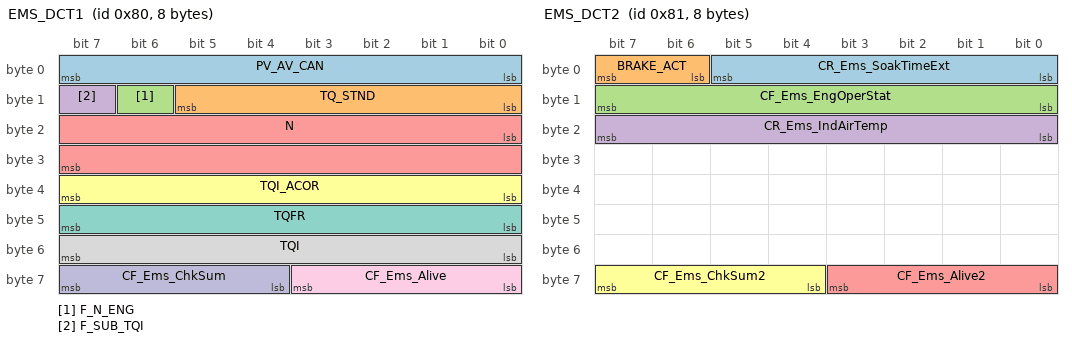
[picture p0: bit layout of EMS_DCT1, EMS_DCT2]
BO_ 128 EMS_DCT1: 8 XXX
    SG_ PV_AV_CAN : 0|8@1+ (0.3906,0) [0|99.603] "%" XXX
    SG_ TQ_STND : 8|6@1+ (10,0) [0|630] "Nm" XXX
    SG_ F_N_ENG : 14|1@1+ (1,0) [0|1] "" XXX
    SG_ F_SUB_TQI : 15|1@1+ (1,0) [0|1] "" XXX
    SG_ N : 16|16@1+ (0.25,0) [0|16383.8] "rpm" XXX
    SG_ TQI_ACOR : 32|8@1+ (0.390625,0) [0|99.6094] "%" XXX
    SG_ TQFR : 40|8@1+ (0.390625,0) [0|99.6094] "%" XXX
    SG_ TQI : 48|8@1+ (0.390625,0) [0|99.6094] "%" XXX
    SG_ CF_Ems_Alive : 56|4@1+ (1,0) [0|15] "" XXX
    SG_ CF_Ems_ChkSum : 60|4@1+ (1,0) [0|15] "" XXX

BO_ 129 EMS_DCT2: 8 XXX
    SG_ CR_Ems_SoakTimeExt : 0|6@1+ (5,0) [0|315] "Min" XXX
    SG_ BRAKE_ACT : 6|2@1+ (1,0) [0|3] "" XXX
    SG_ CF_Ems_EngOperStat : 8|8@1+ (1,0) [0|255] "" XXX
    SG_ CR_Ems_IndAirTemp : 16|8@1+ (0.75,-48) [-48|143.25] "" XXX
    SG_ CF_Ems_Alive2 : 56|4@1+ (1,0) [0|15] "" XXX
    SG_ CF_Ems_ChkSum2 : 60|4@1+ (1,0) [0|15] "" XXX

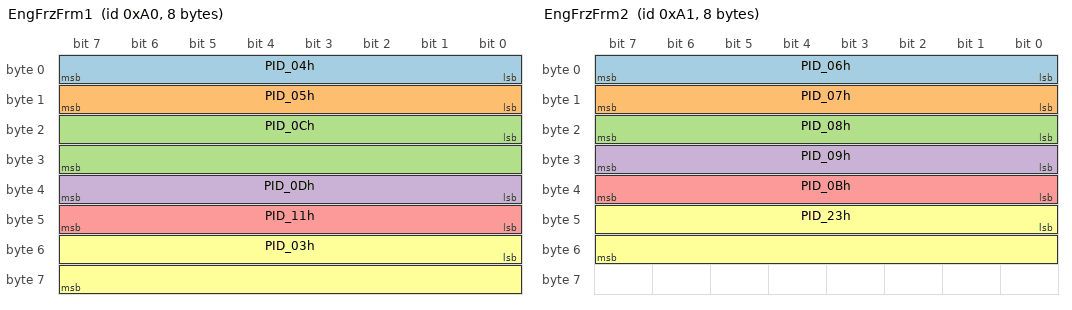
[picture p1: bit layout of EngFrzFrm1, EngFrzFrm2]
BO_ 160 EngFrzFrm1: 8 XXX
    SG_ PID_04h : 0|8@1+ (0.392157,0) [0|100] "%" XXX
    SG_ PID_05h : 8|8@1+ (1,-40) [-40|215] "" XXX
    SG_ PID_0Ch : 16|16@1+ (0.25,0) [0|16383.8] "rpm" XXX
    SG_ PID_0Dh : 32|8@1+ (1,0) [0|255] "km/h" XXX
    SG_ PID_11h : 40|8@1+ (0.392157,0) [0|100] "%" XXX
    SG_ PID_03h : 48|16@1+ (1,0) [0|65535] "" XXX

BO_ 161 EngFrzFrm2: 8 XXX
    SG_ PID_06h : 0|8@1+ (0.78125,-100) [-100|99.22] "%" XXX
    SG_ PID_07h : 8|8@1+ (0.78125,-100) [-100|99.22] "%" XXX
    SG_ PID_08h : 16|8@1+ (0.78125,-100) [-100|99.22] "%" XXX
    SG_ PID_09h : 24|8@1+ (0.78125,-100) [-100|99.22] "%" XXX
    SG_ PID_0Bh : 32|8@1+ (1,0) [0|255] "kPa" XXX
    SG_ PID_23h : 40|16@1+ (10,0) [0|655350] "kPa" XXX

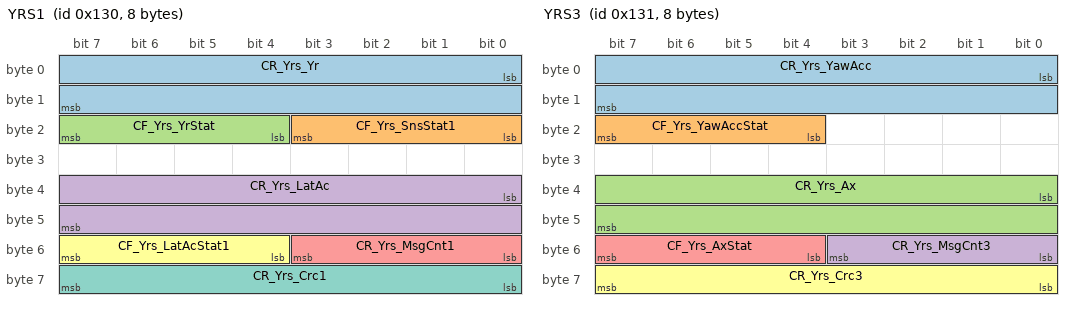
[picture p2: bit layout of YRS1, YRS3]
BO_ 304 YRS1: 8 XXX
    SG_ CR_Yrs_Yr : 0|16@1+ (0.005,-163.84) [-163.84|163.83] "" XXX
    SG_ CF_Yrs_SnsStat1 : 16|4@1+ (1,0) [0|15] "" XXX
    SG_ CF_Yrs_YrStat : 20|4@1+ (1,0) [0|15] "" XXX
    SG_ CR_Yrs_LatAc : 32|16@1+ (0.000127465,-4.17677) [-4.17677|4.17652] "g" XXX
    SG_ CR_Yrs_MsgCnt1 : 48|4@1+ (1,0) [0|15] "" XXX
    SG_ CF_Yrs_LatAcStat1 : 52|4@1+ (1,0) [0|15] "" XXX
    SG_ CR_Yrs_Crc1 : 56|8@1+ (1,0) [0|255] "" XXX

BO_ 305 YRS3: 8 XXX
    SG_ CR_Yrs_YawAcc : 0|16@1+ (0.125,-4096) [-4096|4095.75] "" XXX
    SG_ CF_Yrs_YawAccStat : 20|4@1+ (1,0) [0|15] "" XXX
    SG_ CR_Yrs_Ax : 32|16@1+ (0.000127465,-4.17677) [-4.17677|4.17652] "g" XXX
    SG_ CR_Yrs_MsgCnt3 : 48|4@1+ (1,0) [0|15] "" XXX
    SG_ CF_Yrs_AxStat : 52|4@1+ (1,0) [0|15] "" XXX
    SG_ CR_Yrs_Crc3 : 56|8@1+ (1,0) [0|255] "" XXX

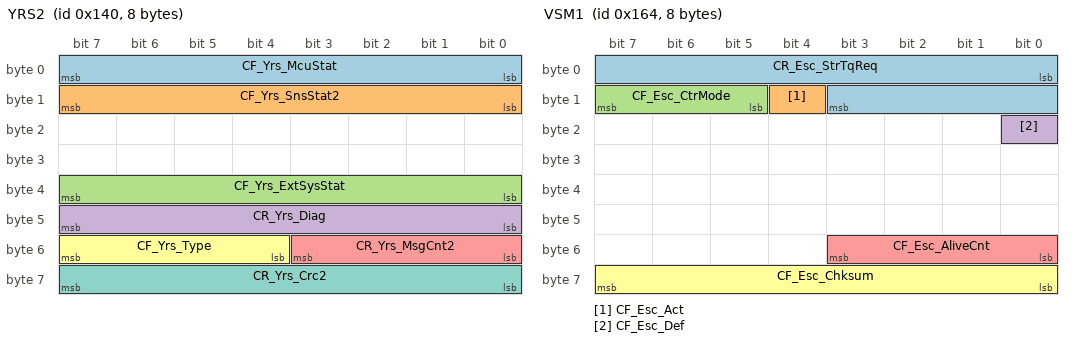
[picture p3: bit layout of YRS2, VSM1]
BO_ 320 YRS2: 8 XXX
    SG_ CF_Yrs_McuStat : 0|8@1+ (1,0) [0|255] "" XXX
    SG_ CF_Yrs_SnsStat2 : 8|8@1+ (1,0) [0|255] "" XXX
    SG_ CF_Yrs_ExtSysStat : 32|8@1+ (1,0) [0|255] "" XXX
    SG_ CR_Yrs_Diag : 40|8@1+ (1,0) [0|255] "" XXX
    SG_ CR_Yrs_MsgCnt2 : 48|4@1+ (1,0) [0|15] "" XXX
    SG_ CF_Yrs_Type : 52|4@1+ (1,0) [0|15] "" XXX
    SG_ CR_Yrs_Crc2 : 56|8@1+ (1,0) [0|255] "" XXX

BO_ 339 TCS1: 8 XXX
    SG_ TCS_REQ : 0|1@1+ (1,0) [0|1] "" XXX
    SG_ MSR_C_REQ : 1|1@1+ (1,0) [0|1] "" XXX
    SG_ TCS_PAS : 2|1@1+ (1,0) [0|1] "" XXX
    SG_ TCS_GSC : 3|1@1+ (1,0) [0|1] "" XXX
    SG_ CF_Esc_LimoInfo : 4|2@1+ (1,0) [0|3] "" XXX
    SG_ ABS_DIAG : 6|1@1+ (1,0) [0|1] "" XXX
    SG_ ABS_DEF : 7|1@1+ (1,0) [0|1] "" XXX
    SG_ TCS_DEF : 8|1@1+ (1,0) [0|1] "" XXX
    SG_ TCS_CTL : 9|1@1+ (1,0) [0|1] "" XXX
    SG_ ABS_ACT : 10|1@1+ (1,0) [0|1] "" XXX
    SG_ EBD_DEF : 11|1@1+ (1,0) [0|1] "" XXX
    SG_ ESP_PAS : 12|1@1+ (1,0) [0|1] "" XXX
    SG_ ESP_DEF : 13|1@1+ (1,0) [0|1] "" XXX
    SG_ ESP_CTL : 14|1@1+ (1,0) [0|1] "" XXX
    SG_ TCS_MFRN : 15|1@1+ (1,0) [0|1] "" XXX
    SG_ DBC_CTL : 16|1@1+ (1,0) [0|1] "" XXX
    SG_ DBC_PAS : 17|1@1+ (1,0) [0|1] "" XXX
    SG_ DBC_DEF : 18|1@1+ (1,0) [0|1] "" XXX
    SG_ HAC_CTL : 19|1@1+ (1,0) [0|1] "" XXX
    SG_ HAC_PAS : 20|1@1+ (1,0) [0|1] "" XXX
    SG_ HAC_DEF : 21|1@1+ (1,0) [0|1] "" XXX
    SG_ ESS_STAT : 22|2@1+ (1,0) [0|3] "" XXX
    SG_ TQI_TCS : 24|8@1+ (0.390625,0) [0|99.6094] "%" XXX
    SG_ TQI_MSR : 32|8@1+ (0.390625,0) [0|99.6094] "%" XXX
    SG_ TQI_SLW_TCS : 40|8@1+ (0.390625,0) [0|99.6094] "%" XXX
    SG_ CF_Esc_BrkCtl : 48|1@1+ (1,0) [0|1] "" XXX
    SG_ ESC_OFF_STEP : 49|2@1+ (1,0) [0|3] "" XXX
    SG_ _4WD_Status : 51|1@1+ (1,0) [0|1] "" XXX
    SG_ AliveCounter_TCS1 : 52|4@1+ (1,0) [0|1] "" XXX
    SG_ CheckSum_TCS1 : 56|8@1+ (1,0) [0|1] "" XXX

BO_ 356 VSM1: 8 XXX
    SG_ CR_Esc_StrTqReq : 0|12@1+ (0.01,-20.48) [-20.48|20.47] "Nm" XXX
    SG_ CF_Esc_Act : 12|1@1+ (1,0) [0|1] "" XXX
    SG_ CF_Esc_CtrMode : 13|3@1+ (1,0) [0|7] "" XXX
    SG_ CF_Esc_Def : 16|1@1+ (1,0) [0|1] "" XXX
    SG_ CF_Esc_AliveCnt : 48|4@1+ (1,0) [0|15] "" XXX
    SG_ CF_Esc_Chksum : 56|8@1+ (1,0) [0|255] "" XXX

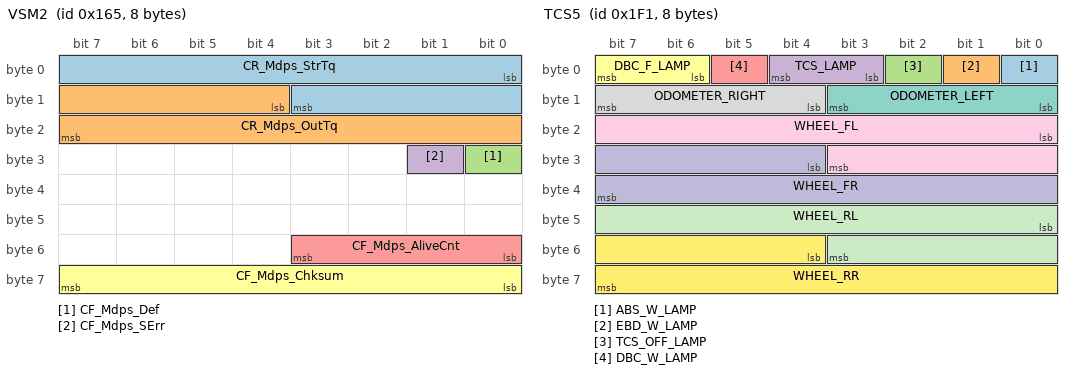
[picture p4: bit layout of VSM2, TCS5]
BO_ 357 VSM2: 8 XXX
    SG_ CR_Mdps_StrTq : 0|12@1+ (0.01,-20.48) [-20.48|20.47] "Nm" XXX
    SG_ CR_Mdps_OutTq : 12|12@1+ (0.1,-204.8) [-204.8|204.7] "" XXX
    SG_ CF_Mdps_Def : 24|1@1+ (1,0) [0|1] "" XXX
    SG_ CF_Mdps_SErr : 25|1@1+ (1,0) [0|1] "" XXX
    SG_ CF_Mdps_AliveCnt : 48|4@1+ (1,0) [0|15] "" XXX
    SG_ CF_Mdps_Chksum : 56|8@1+ (1,0) [0|255] "" XXX

BO_ 399 EMS_H2: 8 XXX
    SG_ R_TqAcnApvC : 0|8@1+ (0.2,0) [0|51] "Nm" XXX
    SG_ R_PAcnC : 8|8@1+ (125,0) [0|31875] "hPa" XXX
    SG_ TQI_B : 16|8@1+ (0.390625,0) [0|99.6094] "%" XXX
    SG_ SLD_VS : 24|8@1+ (1,0) [0|255] "km/h" XXX
    SG_ CF_CdaStat : 32|3@1+ (1,0) [0|7] "" XXX
    SG_ CF_Ems_IsgStat : 35|3@1+ (1,0) [0|7] "" XXX
    SG_ CF_Ems_OilChg : 38|1@1+ (1,0) [0|1] "" XXX
    SG_ CF_Ems_EtcLimpMod : 39|1@1+ (1,0) [0|1] "" XXX
    SG_ R_NEngIdlTgC : 40|8@1+ (10,0) [0|2550] "rpm" XXX
    SG_ CF_Ems_UpTarGr : 48|1@1+ (1,0) [0|1] "" XXX
    SG_ CF_Ems_DownTarGr : 49|1@1+ (1,0) [0|1] "" XXX
    SG_ CF_Ems_DesCurGr : 50|4@1+ (1,0) [0|15] "" XXX
    SG_ CF_Ems_SldAct : 54|1@1+ (1,0) [0|1] "" XXX
    SG_ CF_Ems_SldPosAct : 55|1@1+ (1,0) [0|1] "" XXX
    SG_ CF_Ems_HPresStat : 56|1@1+ (1,0) [0|1] "" XXX
    SG_ CF_Ems_IsgBuz : 57|1@1+ (1,0) [0|1] "" XXX
    SG_ CF_Ems_IdlStpFCO : 58|1@1+ (1,0) [0|1] "" XXX
    SG_ CF_Ems_FCopen : 59|1@1+ (1,0) [0|1] "" XXX
    SG_ CF_Ems_ActEcoAct : 60|1@1+ (1,0) [0|1] "" XXX
    SG_ CF_Ems_EngRunNorm : 61|1@1+ (1,0) [0|1] "" XXX
    SG_ CF_Ems_IsgStat2 : 62|2@1+ (2,0) [0|3] "" XXX

BO_ 497 TCS5: 8 XXX
    SG_ ABS_W_LAMP : 0|1@1+ (1,0) [0|1] "" XXX
    SG_ EBD_W_LAMP : 1|1@1+ (1,0) [0|1] "" XXX
    SG_ TCS_OFF_LAMP : 2|1@1+ (1,0) [0|1] "" XXX
    SG_ TCS_LAMP : 3|2@1+ (1,0) [0|3] "" XXX
    SG_ DBC_W_LAMP : 5|1@1+ (1,0) [0|1] "" XXX
    SG_ DBC_F_LAMP : 6|2@1+ (1,0) [0|3] "" XXX
    SG_ ODOMETER_LEFT : 8|4@1+ (1,0) [0|15] "m" XXX
    SG_ ODOMETER_RIGHT : 12|4@1+ (1,0) [0|15] "m" XXX
    SG_ WHEEL_FL : 16|12@1+ (0.125,0) [0|511.875] "km/h" XXX
    SG_ WHEEL_FR : 28|12@1+ (0.125,0) [0|511.875] "km/h" XXX
    SG_ WHEEL_RL : 40|12@1+ (0.125,0) [0|511.875] "km/h" XXX
    SG_ WHEEL_RR : 52|12@1+ (0.125,0) [0|511.875] "km/h" XXX

BO_ 544 ESP2: 8 XXX
    SG_ LAT_ACCEL : 0|11@1+ (0.01,-10.23) [-10.23|10.24] "m/s^2" XXX
    SG_ ESP2_AliveCounter_LSB : 11|3@1+ (1,0) [0|7] "" XXX
    SG_ LAT_ACCEL_STAT : 14|1@1+ (1,0) [0|1] "" XXX
    SG_ LAT_ACCEL_DIAG : 15|1@1+ (1,0) [0|1] "" XXX
    SG_ LONG_ACCEL : 16|11@1+ (0.01,-10.23) [-10.23|10.24] "m/s^2" XXX
    SG_ ESP2_AliveCounter_MSB : 27|1@1+ (1,0) [0|1] "" XXX
    SG_ ESP2_Checksum_LSB : 28|2@1+ (1,0) [0|3] "" XXX
    SG_ LONG_ACCEL_STAT : 30|1@1+ (1,0) [0|1] "" XXX
    SG_ LONG_ACCEL_DIAG : 31|1@1+ (1,0) [0|1] "" XXX
    SG_ CYL_PRES : 32|12@1+ (0.1,0) [0|409.5] "Bar" XXX
    SG_ ESP12_Checksum_MSB : 44|2@1+ (1,0) [0|3] "" XXX
    SG_ CYL_PRES_STAT : 46|1@1+ (1,0) [0|1] "" XXX
    SG_ CYL_PRESS_DIAG : 47|1@1+ (1,0) [0|1] "" XXX
    SG_ YAW_RATE : 48|13@1+ (0.01,-40.95) [-40.95|40.96] "" XXX
    SG_ CYL_PRES_FLAG : 61|1@1+ (1,0) [0|1] "" XXX
    SG_ YAW_RATE_STAT : 62|1@1+ (1,0) [0|1] "" XXX
    SG_ YAW_RATE_DIAG : 63|1@1+ (1,0) [0|1] "" XXX

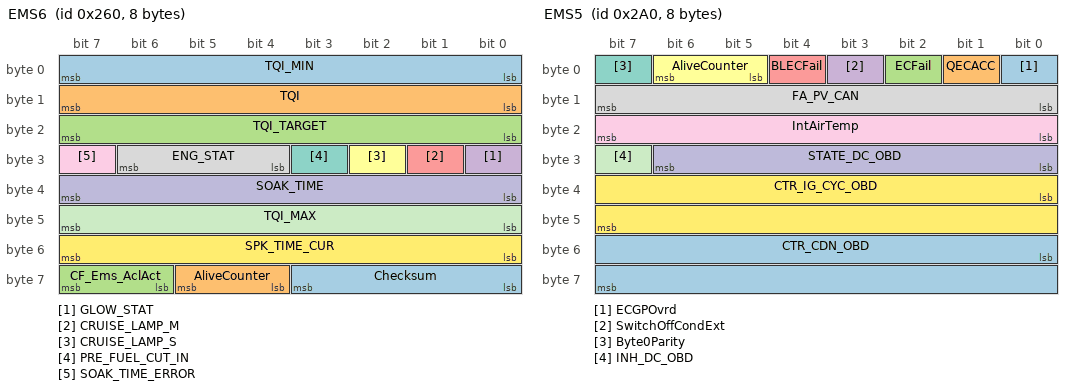
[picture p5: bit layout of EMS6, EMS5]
BO_ 608 EMS6: 8 XXX
    SG_ TQI_MIN : 0|8@1+ (0.390625,0) [0|99.6094] "%" XXX
    SG_ TQI : 8|8@1+ (0.390625,0) [0|99.6094] "%" XXX
    SG_ TQI_TARGET : 16|8@1+ (0.390625,0) [0|99.6094] "%" XXX
    SG_ GLOW_STAT : 24|1@1+ (1,0) [0|1] "" XXX
    SG_ CRUISE_LAMP_M : 25|1@1+ (1,0) [0|1] "" XXX
    SG_ CRUISE_LAMP_S : 26|1@1+ (1,0) [0|1] "" XXX
    SG_ PRE_FUEL_CUT_IN : 27|1@1+ (1,0) [0|1] "" XXX
    SG_ ENG_STAT : 28|3@1+ (1,0) [0|7] "" XXX
    SG_ SOAK_TIME_ERROR : 31|1@1+ (1,0) [0|1] "" XXX
    SG_ SOAK_TIME : 32|8@1+ (1,0) [0|255] "Min" XXX
    SG_ TQI_MAX : 40|8@1+ (0.390625,0) [0|99.6094] "%" XXX
    SG_ SPK_TIME_CUR : 48|8@1+ (0.375,-35.625) [-35.625|60] "" XXX
    SG_ Checksum : 56|4@1+ (1,0) [0|15] "" XXX
    SG_ AliveCounter : 60|2@1+ (1,0) [0|3] "" XXX
    SG_ CF_Ems_AclAct : 62|2@1+ (1,0) [0|3] "" XXX

BO_ 672 EMS5: 8 XXX
    SG_ ECGPOvrd : 0|1@1+ (1,0) [0|1] "" XXX
    SG_ QECACC : 1|1@1+ (1,0) [0|1] "" XXX
    SG_ ECFail : 2|1@1+ (1,0) [0|1] "" XXX
    SG_ SwitchOffCondExt : 3|1@1+ (1,0) [0|1] "" XXX
    SG_ BLECFail : 4|1@1+ (1,0) [0|1] "" XXX
    SG_ AliveCounter : 5|2@1+ (1,0) [0|3] "" XXX
    SG_ Byte0Parity : 7|1@1+ (1,0) [0|1] "" XXX
    SG_ FA_PV_CAN : 8|8@1+ (0.3906,0) [0|99.2] "%" XXX
    SG_ IntAirTemp : 16|8@1+ (0.75,-48) [-48|143.25] "" XXX
    SG_ STATE_DC_OBD : 24|7@1+ (1,0) [0|127] "" XXX
    SG_ INH_DC_OBD : 31|1@1+ (1,0) [0|1] "" XXX
    SG_ CTR_IG_CYC_OBD : 32|16@1+ (1,0) [0|65535] "" XXX
    SG_ CTR_CDN_OBD : 48|16@1+ (1,0) [0|65535] "" XXX

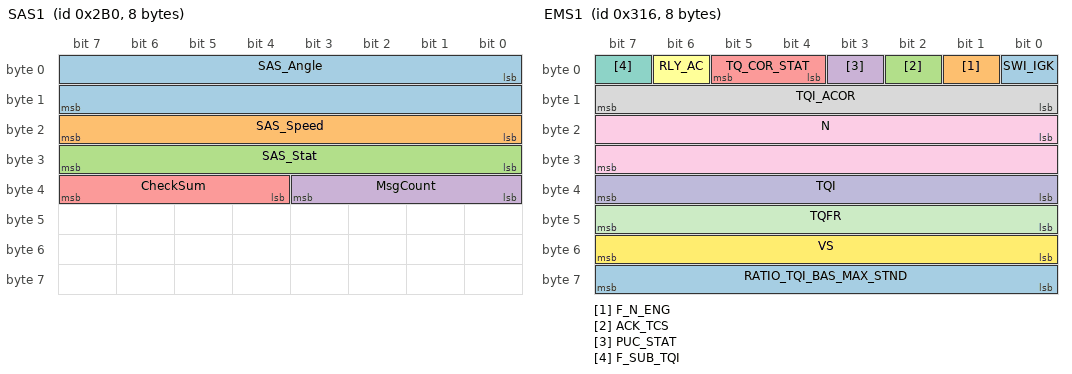
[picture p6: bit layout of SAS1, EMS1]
BO_ 688 SAS1: 8 XXX
    SG_ SAS_Angle : 0|16@1+ (0.1,0) [-3276.8|3276.7] "Deg" XXX
    SG_ SAS_Speed : 16|8@1+ (4,0) [0|1016] "" XXX
    SG_ SAS_Stat : 24|8@1+ (1,0) [0|255] "" XXX
    SG_ MsgCount : 32|4@1+ (1,0) [0|15] "" XXX
    SG_ CheckSum : 36|4@1+ (1,0) [0|15] "" XXX

BO_ 790 EMS1: 8 XXX
    SG_ SWI_IGK : 0|1@1+ (1,0) [0|1] "" XXX
    SG_ F_N_ENG : 1|1@1+ (1,0) [0|1] "" XXX
    SG_ ACK_TCS : 2|1@1+ (1,0) [0|1] "" XXX
    SG_ PUC_STAT : 3|1@1+ (1,0) [0|1] "" XXX
    SG_ TQ_COR_STAT : 4|2@1+ (1,0) [0|3] "" XXX
    SG_ RLY_AC : 6|1@1+ (1,0) [0|1] "" XXX
    SG_ F_SUB_TQI : 7|1@1+ (1,0) [0|1] "" XXX
    SG_ TQI_ACOR : 8|8@1+ (0.390625,0) [0|99.6094] "%" XXX
    SG_ N : 16|16@1+ (0.25,0) [0|16383.8] "rpm" XXX
    SG_ TQI : 32|8@1+ (0.390625,0) [0|99.6094] "%" XXX
    SG_ TQFR : 40|8@1+ (0.390625,0) [0|99.6094] "%" XXX
    SG_ VS : 48|8@1+ (1,0) [0|254] "km/h" XXX
    SG_ RATIO_TQI_BAS_MAX_STND : 56|8@1+ (0.0078,0) [0|2] "" XXX

BO_ 809 EMS2: 8 XXX
    SG_ TQ_STND : 0|6@1+ (10,0) [0|630] "Nm" XXX
    SG_ CAN_VERS : 0|6@1+ (1,0) [0|7.7] "" XXX
    SG_ CONF_TCU : 0|6@1+ (1,0) [0|63] "" XXX
    SG_ OBD_FRF_ACK : 0|6@1+ (1,0) [0|63] "" XXX
    SG_ MUL_CODE : 6|2@1+ (1,0) [0|3] "" XXX
    SG_ TEMP_ENG : 8|8@1+ (0.75,-48) [-48|143.25] "" XXX
    SG_ MAF_FAC_ALTI_MMV : 16|8@1+ (0.00781,0) [0|1.99155] "" XXX
    SG_ VB_OFF_ACT : 24|1@1+ (1,0) [0|1] "" XXX
    SG_ ACK_ES : 25|1@1+ (1,0) [0|1] "" XXX
    SG_ CONF_MIL_FMY : 26|3@1+ (1,0) [0|7] "" XXX
    SG_ OD_OFF_REQ : 29|1@1+ (1,0) [0|1] "" XXX
    SG_ ACC_ACT : 30|1@1+ (1,0) [0|1] "" XXX
    SG_ CLU_ACK : 31|1@1+ (1,0) [0|1] "" XXX
    SG_ BRAKE_ACT : 32|2@1+ (1,0) [0|3] "" XXX
    SG_ ENG_CHR : 34|4@1+ (1,0) [0|15] "" XXX
    SG_ GP_CTL : 38|2@1+ (1,0) [0|3] "" XXX
    SG_ TPS : 40|8@1+ (0.469484,-15.0235) [-15.0235|104.695] "%" XXX
    SG_ PV_AV_CAN : 48|8@1+ (0.3906,0) [0|99.603] "%" XXX
    SG_ ENG_VOL : 56|8@1+ (0.1,0) [0|25.5] "liter" XXX

BO_ 848 FATC: 8 XXX
    SG_ CR_Fatc_TqAcnOut : 0|8@1+ (0.2,0) [0|50.8] "Nm" XXX
    SG_ CF_Fatc_AcnRqSwi : 8|1@1+ (1,0) [0|1] "" XXX
    SG_ CF_Fatc_AcnCltEnRq : 9|1@1+ (1,0) [0|1] "" XXX
    SG_ CF_Fatc_EcvFlt : 10|1@1+ (1,0) [0|1] "" XXX
    SG_ CF_Fatc_BlwrOn : 11|1@1+ (1,0) [0|1] "" XXX
    SG_ CF_FATC_Iden : 12|2@1+ (1,0) [0|3] "" XXX
    SG_ CF_Fatc_BlwrMax : 14|1@1+ (1,0) [0|1] "" XXX
    SG_ CF_Fatc_EngStartReq : 15|1@1+ (1,0) [0|1] "" XXX
    SG_ CF_Fatc_IsgStopReq : 16|1@1+ (1,0) [0|1] "" XXX
    SG_ CF_Fatc_CtrInf : 17|3@1+ (1,0) [0|7] "" XXX
    SG_ CF_Fatc_MsgCnt : 20|4@1+ (1,0) [0|15] "" XXX
    SG_ CR_Fatc_OutTemp : 24|8@1+ (0.5,-40) [-40|60] "" XXX
    SG_ CR_Fatc_OutTempSns : 32|8@1+ (0.5,-40) [-40|60] "" XXX
    SG_ CF_Fatc_Compload : 40|3@1+ (1,0) [0|7] "" XXX
    SG_ CF_Fatc_ActiveEco : 43|1@1+ (1,0) [0|1] "" XXX
    SG_ CF_Fatc_AutoActivation : 44|1@1+ (1,0) [0|1] "" XXX
    SG_ CF_Fatc_DefSw : 45|1@1+ (1,0) [0|1] "" XXX
    SG_ CF_Fatc_PtcRlyStat : 46|1@1+ (1,0) [0|1] "" XXX
    SG_ CF_Fatc_ChkSum : 56|8@1+ (1,0) [0|255] "" XXX

BO_ 880 TCU3: 8 XXX
    SG_ N_TGT_LUP : 0|8@1+ (10,500) [500|3040] "rpm" XXX
    SG_ SLOPE_TCU : 8|6@1+ (0.5,-16) [-16|15.5] "%" XXX
    SG_ CF_Tcu_InhCda : 14|1@1+ (1,0) [0|1] "" XXX
    SG_ CF_Tcu_IsgInhib : 15|1@1+ (1,0) [0|1] "" XXX
    SG_ CF_Tcu_BkeOnReq : 16|2@1+ (1,0) [0|3] "" XXX
    SG_ CF_Tcu_NCStat : 18|2@1+ (1,0) [0|3] "" XXX
    SG_ CF_Tcu_TarGr : 20|4@1+ (1,0) [0|15] "" XXX
    SG_ CF_Tcu_ShfPatt : 24|4@1+ (1,0) [0|15] "" XXX
    SG_ CF_Tcu_InhVis : 28|1@1+ (1,0) [0|1] "" XXX
    SG_ CF_Tcu_PRelReq : 29|1@1+ (1,0) [0|1] "" XXX
    SG_ CF_Tcu_ITPhase : 30|1@1+ (1,0) [0|1] "" XXX
    SG_ CF_Tcu_ActEcoRdy : 31|1@1+ (1,0) [0|1] "" XXX
    SG_ CF_Tcu_TqGrdLim : 32|8@1+ (10,0) [0|2540] "Nm/s" XXX
    SG_ CR_Tcu_IsgTgtRPM : 40|8@1+ (20,0) [0|3500] "rpm" XXX
    SG_ TQI_TCU_INC : 48|8@1+ (0.390625,0) [0|99.6094] "%" XXX
    SG_ CF_Tcu_SbwPInfo : 56|1@1+ (1,0) [0|1] "" XXX
    SG_ CF_Tcu_SptRdy : 57|1@1+ (1,0) [0|1] "" XXX
    SG_ CF_Tcu_Alive3 : 58|2@1+ (1,0) [0|3] "" XXX
    SG_ CF_Tcu_ChkSum3 : 60|4@1+ (1,0) [0|15] "" XXX

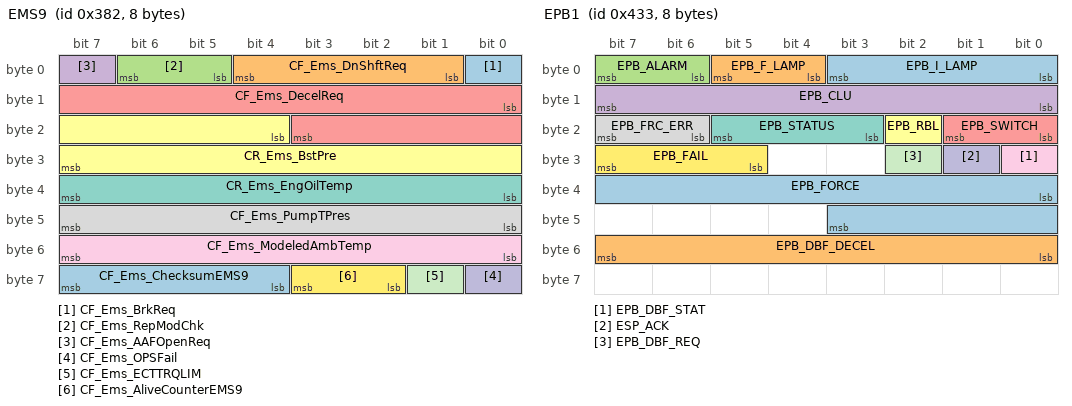
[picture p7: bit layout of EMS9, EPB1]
BO_ 898 EMS9: 8 XXX
    SG_ CF_Ems_BrkReq : 0|1@1+ (1,0) [0|1] "" XXX
    SG_ CF_Ems_DnShftReq : 1|4@1+ (1,0) [0|14] "" XXX
    SG_ CF_Ems_RepModChk : 5|2@1+ (1,0) [0|3] "" XXX
    SG_ CF_Ems_AAFOpenReq : 7|1@1+ (1,0) [0|1] "" XXX
    SG_ CF_Ems_DecelReq : 8|12@1+ (0.001,-4.094) [-4.094|0] "m/s^2" XXX
    SG_ CR_Ems_BstPre : 20|12@1+ (1.322,0) [0|4094] "hPa" XXX
    SG_ CR_Ems_EngOilTemp : 32|8@1+ (0.75,-40) [0|254] "" XXX
    SG_ CF_Ems_PumpTPres : 40|8@1+ (3.13725,0) [0|800] "kPa" XXX
    SG_ CF_Ems_ModeledAmbTemp : 48|8@1+ (0.5,-41) [-40|60] "" XXX
    SG_ CF_Ems_OPSFail : 56|1@1+ (1,0) [0|1] "" XXX
    SG_ CF_Ems_ECTTRQLIM : 57|1@1+ (1,0) [0|1] "" XXX
    SG_ CF_Ems_AliveCounterEMS9 : 58|2@1+ (1,0) [0|3] "" XXX
    SG_ CF_Ems_ChecksumEMS9 : 60|4@1+ (1,0) [0|15] "" XXX

BO_ 1075 EPB1: 8 XXX
    SG_ EPB_I_LAMP : 0|4@1+ (1,0) [0|15] "" XXX
    SG_ EPB_F_LAMP : 4|2@1+ (1,0) [0|3] "" XXX
    SG_ EPB_ALARM : 6|2@1+ (1,0) [0|3] "" XXX
    SG_ EPB_CLU : 8|8@1+ (1,0) [0|255] "" XXX
    SG_ EPB_SWITCH : 16|2@1+ (1,0) [0|3] "" XXX
    SG_ EPB_RBL : 18|1@1+ (1,0) [0|1] "" XXX
    SG_ EPB_STATUS : 19|3@1+ (1,0) [0|7] "" XXX
    SG_ EPB_FRC_ERR : 22|2@1+ (1,0) [0|3] "" XXX
    SG_ EPB_DBF_STAT : 24|1@1+ (1,0) [0|1] "" XXX
    SG_ ESP_ACK : 25|1@1+ (1,0) [0|1] "" XXX
    SG_ EPB_DBF_REQ : 26|1@1+ (1,0) [0|1] "" XXX
    SG_ EPB_FAIL : 29|3@1+ (1,0) [0|7] "" XXX
    SG_ EPB_FORCE : 32|12@1+ (1,-1000) [-1000|3000] "" XXX
    SG_ EPB_DBF_DECEL : 48|8@1+ (0.01,0) [0|2.54] "g" XXX

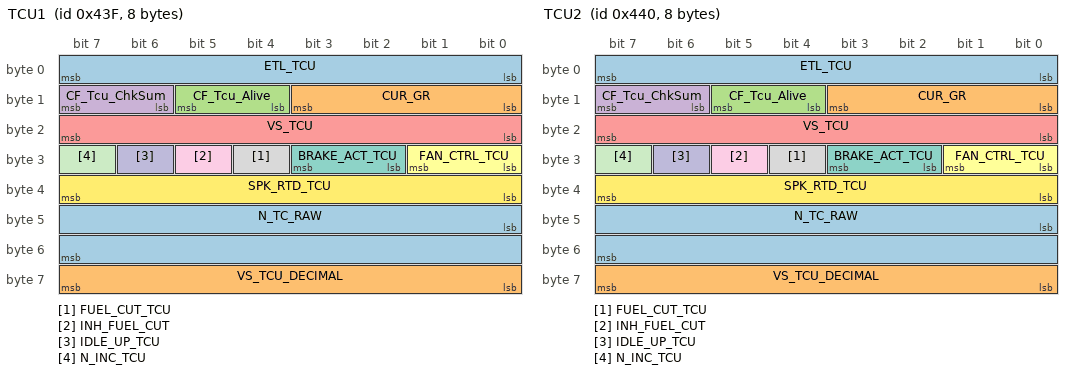
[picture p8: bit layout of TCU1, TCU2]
BO_ 1087 TCU1: 8 XXX
    SG_ ETL_TCU : 0|8@1+ (2,0) [0|508] "Nm" XXX
    SG_ CUR_GR : 8|4@1+ (1,0) [0|15] "" XXX
    SG_ CF_Tcu_Alive : 12|2@1+ (1,0) [0|3] "" XXX
    SG_ CF_Tcu_ChkSum : 14|2@1+ (1,0) [0|3] "" XXX
    SG_ VS_TCU : 16|8@1+ (1,0) [0|254] "km/h" XXX
    SG_ FAN_CTRL_TCU : 24|2@1+ (1,0) [0|3] "" XXX
    SG_ BRAKE_ACT_TCU : 26|2@1+ (1,0) [0|3] "" XXX
    SG_ FUEL_CUT_TCU : 28|1@1+ (1,0) [0|1] "" XXX
    SG_ INH_FUEL_CUT : 29|1@1+ (1,0) [0|1] "" XXX
    SG_ IDLE_UP_TCU : 30|1@1+ (1,0) [0|1] "" XXX
    SG_ N_INC_TCU : 31|1@1+ (1,0) [0|1] "" XXX
    SG_ SPK_RTD_TCU : 32|8@1+ (0.375,-23.625) [-15|15] "" XXX
    SG_ N_TC_RAW : 40|16@1+ (0.25,0) [0|16383.5] "rpm" XXX
    SG_ VS_TCU_DECIMAL : 56|8@1+ (0.0078125,0) [0|0.992188] "km/h" XXX

BO_ 1088 TCU2: 8 XXX
    SG_ ETL_TCU : 0|8@1+ (2,0) [0|508] "Nm" XXX
    SG_ CUR_GR : 8|4@1+ (1,0) [0|15] "" XXX
    SG_ CF_Tcu_Alive : 12|2@1+ (1,0) [0|3] "" XXX
    SG_ CF_Tcu_ChkSum : 14|2@1+ (1,0) [0|3] "" XXX
    SG_ VS_TCU : 16|8@1+ (1,0) [0|254] "km/h" XXX
    SG_ FAN_CTRL_TCU : 24|2@1+ (1,0) [0|3] "" XXX
    SG_ BRAKE_ACT_TCU : 26|2@1+ (1,0) [0|3] "" XXX
    SG_ FUEL_CUT_TCU : 28|1@1+ (1,0) [0|1] "" XXX
    SG_ INH_FUEL_CUT : 29|1@1+ (1,0) [0|1] "" XXX
    SG_ IDLE_UP_TCU : 30|1@1+ (1,0) [0|1] "" XXX
    SG_ N_INC_TCU : 31|1@1+ (1,0) [0|1] "" XXX
    SG_ SPK_RTD_TCU : 32|8@1+ (0.375,-23.625) [-15|15] "" XXX
    SG_ N_TC_RAW : 40|16@1+ (0.25,0) [0|16383.5] "rpm" XXX
    SG_ VS_TCU_DECIMAL : 56|8@1+ (0.0078125,0) [0|0.992188] "km/h" XXX

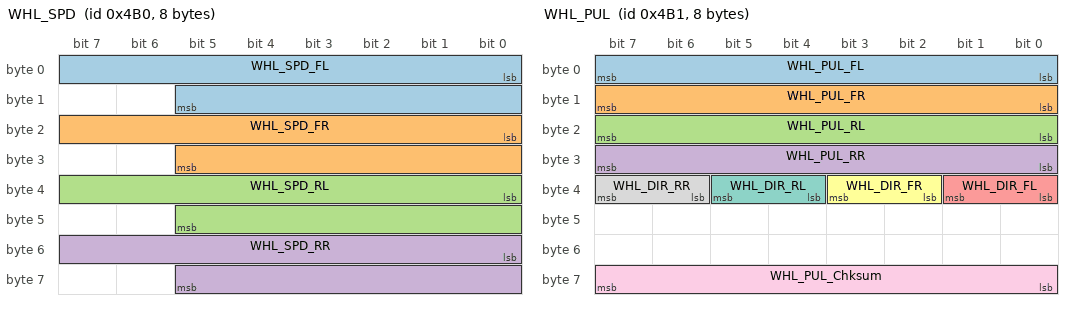
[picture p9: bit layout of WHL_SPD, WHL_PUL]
BO_ 1200 WHL_SPD: 8 XXX
    SG_ WHL_SPD_FL : 0|14@1+ (0.03125,0) [0|511.969] "km/h" XXX
    SG_ WHL_SPD_FR : 16|14@1+ (0.03125,0) [0|511.969] "km/h" XXX
    SG_ WHL_SPD_RL : 32|14@1+ (0.03125,0) [0|511.969] "km/h" XXX
    SG_ WHL_SPD_RR : 48|14@1+ (0.03125,0) [0|511.969] "km/h" XXX

BO_ 1201 WHL_PUL: 8 XXX
    SG_ WHL_PUL_FL : 0|8@1+ (0.5,0) [0|127.5] "pulse count" XXX
    SG_ WHL_PUL_FR : 8|8@1+ (0.5,0) [0|127.5] "pulse count" XXX
    SG_ WHL_PUL_RL : 16|8@1+ (0.5,0) [0|127.5] "pulse count" XXX
    SG_ WHL_PUL_RR : 24|8@1+ (0.5,0) [0|127.5] "pulse count" XXX
    SG_ WHL_DIR_FL : 32|2@1+ (1,0) [0|3] "" XXX
    SG_ WHL_DIR_FR : 34|2@1+ (1,0) [0|3] "" XXX
    SG_ WHL_DIR_RL : 36|2@1+ (1,0) [0|3] "" XXX
    SG_ WHL_DIR_RR : 38|2@1+ (1,0) [0|3] "" XXX
    SG_ WHL_PUL_Chksum : 56|8@1+ (1,0) [0|255] "" XXX

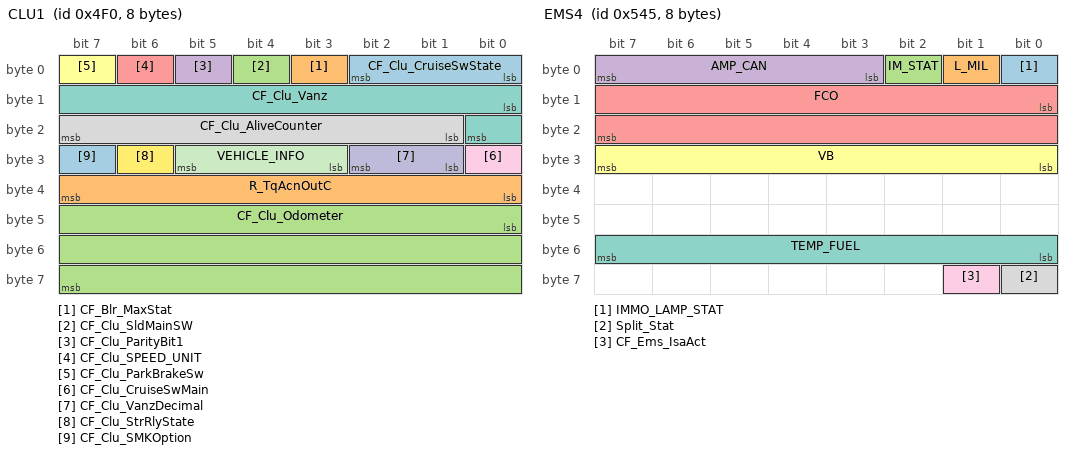
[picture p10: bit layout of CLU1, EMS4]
BO_ 1264 CLU1: 8 XXX
    SG_ CF_Clu_CruiseSwState : 0|3@1+ (1,0) [0|7] "" XXX
    SG_ CF_Blr_MaxStat : 3|1@1+ (1,0) [0|1] "" XXX
    SG_ CF_Clu_SldMainSW : 4|1@1+ (1,0) [0|1] "" XXX
    SG_ CF_Clu_ParityBit1 : 5|1@1+ (1,0) [0|1] "pulse count" XXX
    SG_ CF_Clu_SPEED_UNIT : 6|1@1+ (1,0) [0|1] "" XXX
    SG_ CF_Clu_ParkBrakeSw : 7|1@1+ (1,0) [0|1] "" XXX
    SG_ CF_Clu_Vanz : 8|9@1+ (0.5,0) [0|255.5] "km/h or MPH" XXX
    SG_ CF_Clu_AliveCounter : 17|7@1+ (1,0) [0|127] "" XXX
    SG_ CF_Clu_CruiseSwMain : 24|1@1+ (1,0) [0|1] "" XXX
    SG_ CF_Clu_VanzDecimal : 25|2@1+ (1,0) [0|0.375] "" XXX
    SG_ VEHICLE_INFO : 27|3@1+ (1,0) [0|7] "" XXX
    SG_ CF_Clu_StrRlyState : 30|1@1+ (1,0) [0|1] "" XXX
    SG_ CF_Clu_SMKOption : 31|1@1+ (1,0) [0|1] "" XXX
    SG_ R_TqAcnOutC : 32|8@1+ (1,0) [0|51] "Nm" XXX
    SG_ CF_Clu_Odometer : 40|24@1+ (0.1,0) [0|1.67772e+006] "km" XXX

BO_ 1265 CLU3: 8 XXX
    SG_ CF_Clu_AcnRqSwi : 0|1@1+ (1,0) [0|1] "" XXX
    SG_ CF_Clu_AcnCltEnRq : 1|1@1+ (1,0) [0|1] "" XXX
    SG_ CF_Clu_RefDetMod : 2|1@1+ (1,0) [0|1] "" XXX
    SG_ CF_Clu_DefoggerRly : 5|1@1+ (1,0) [0|1] "" XXX
    SG_ CF_Clu_LowfuelWarn : 16|2@1+ (1,0) [0|3] "" XXX
    SG_ CF_Clu_SportsModeSwi : 18|2@1+ (1,0) [0|3] "" XXX
    SG_ CF_Clu_ALightStat : 20|1@1+ (1,0) [0|1] "" XXX
    SG_ CF_Clu_FrtFog : 21|1@1+ (1,0) [0|1] "" XXX
    SG_ CF_Clu_DetentOut : 22|1@1+ (1,0) [0|1] "" XXX
    SG_ CF_Clu_HeadLampTail : 23|1@1+ (1,0) [0|1] "" XXX
    SG_ CF_Clu_TrailerMode : 24|1@1+ (1,0) [0|1] "" XXX
    SG_ CF_Clu_DTE : 25|10@1+ (1,0) [0|1023] "" XXX
    SG_ CF_Clu_TripUnit : 35|2@1+ (1,0) [0|3] "" XXX
    SG_ CF_Clu_IsaMainSW : 37|1@1+ (1,0) [0|1] "" XXX
    SG_ CF_Clu_FlexSteerSW : 40|1@1+ (1,0) [0|1] "" XXX
    SG_ CF_Clu_AvsmCur : 41|1@1+ (1,0) [0|1] "" XXX
    SG_ CF_Clu_HudSpeedset : 42|1@1+ (1,0) [0|1] "" XXX
    SG_ CF_Clu_HudTbtSet : 43|1@1+ (1,0) [0|1] "" XXX
    SG_ CF_Clu_HudSccSet : 44|1@1+ (1,0) [0|1] "" XXX
    SG_ CF_Clu_HudLdwsSet : 45|1@1+ (1,0) [0|1] "" XXX
    SG_ CF_Clu_HudDisSet : 46|1@1+ (1,0) [0|1] "" XXX
    SG_ CF_Clu_HudFontSizeSet : 47|2@1+ (1,0) [0|3] "" XXX
    SG_ CF_Clu_HudFontColorSet : 49|2@1+ (1,0) [0|3] "" XXX
    SG_ CF_Clu_HudBrightSet : 51|2@1+ (1,0) [0|3] "" XXX
    SG_ CF_Clu_HudHeightSet : 53|2@1+ (1,0) [0|3] "" XXX
    SG_ CF_Clu_CluInfo : 55|1@1+ (1,0) [0|1] "" XXX
    SG_ CF_Clu_RheostatLevel : 56|5@1+ (1,0) [0|31] "" XXX
    SG_ CF_Clu_DrivinglampStat : 61|3@1+ (1,0) [0|7] "" XXX

BO_ 1349 EMS4: 8 XXX
    SG_ IMMO_LAMP_STAT : 0|1@1+ (1,0) [0|1] "" XXX
    SG_ L_MIL : 1|1@1+ (1,0) [0|1] "" XXX
    SG_ IM_STAT : 2|1@1+ (1,0) [0|1] "" XXX
    SG_ AMP_CAN : 3|5@1+ (10.7316,458.98) [458.98|791.66] "mmHg" XXX
    SG_ FCO : 8|16@1+ (0.128,0) [0|8388.48] "ul" XXX
    SG_ VB : 24|8@1+ (0.101563,0) [0|25.8984] "V" XXX
    SG_ TEMP_FUEL : 48|8@1+ (0.75,-48) [-48|143.25] "" XXX
    SG_ Split_Stat : 56|1@1+ (1,0) [0|1] "" XXX
    SG_ CF_Ems_IsaAct : 57|1@1+ (1,0) [0|1] "" XXX

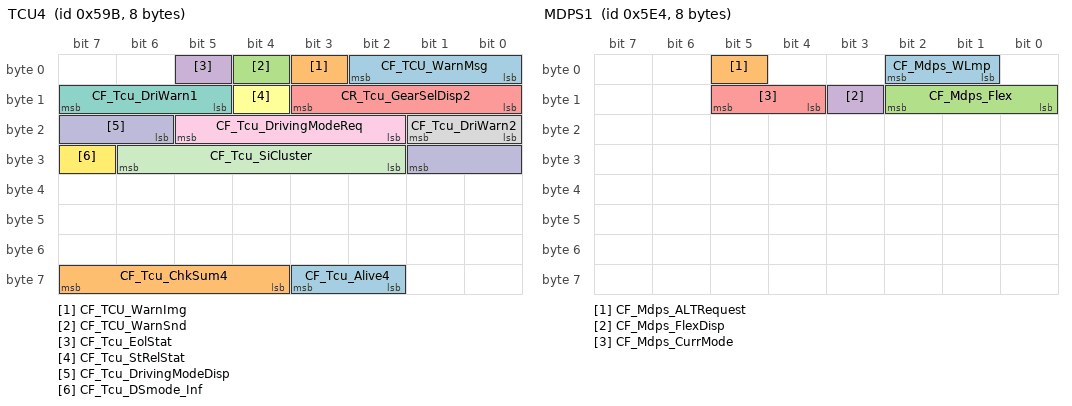
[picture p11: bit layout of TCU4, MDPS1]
BO_ 1435 TCU4: 8 XXX
    SG_ CF_TCU_WarnMsg : 0|3@1+ (1,0) [0|7] "" XXX
    SG_ CF_TCU_WarnImg : 3|1@1+ (1,0) [0|1] "" XXX
    SG_ CF_TCU_WarnSnd : 4|1@1+ (1,0) [0|1] "" XXX
    SG_ CF_Tcu_EolStat : 5|1@1+ (1,0) [0|1] "" XXX
    SG_ CR_Tcu_GearSelDisp2 : 8|4@1+ (1,0) [0|15] "" XXX
    SG_ CF_Tcu_StRelStat : 12|1@1+ (1,0) [0|1] "" XXX
    SG_ CF_Tcu_DriWarn1 : 13|3@1+ (1,0) [0|7] "" XXX
    SG_ CF_Tcu_DriWarn2 : 16|2@1+ (1,0) [0|3] "" XXX
    SG_ CF_Tcu_DrivingModeReq : 18|4@1+ (1,0) [0|0] "" XXX
    SG_ CF_Tcu_DrivingModeDisp : 22|4@1+ (1,0) [0|0] "" XXX
    SG_ CF_Tcu_SiCluster : 26|5@1+ (1,0) [0|0] "" XXX
    SG_ CF_Tcu_DSmode_Inf : 31|1@1+ (1,0) [0|1] "" XXX
    SG_ CF_Tcu_Alive4 : 58|2@1+ (1,0) [0|3] "" XXX
    SG_ CF_Tcu_ChkSum4 : 60|4@1+ (1,0) [0|15] "" XXX

BO_ 1508 MDPS1: 8 XXX
    SG_ CF_Mdps_WLmp : 1|2@1+ (1,0) [0|3] "" XXX
    SG_ CF_Mdps_ALTRequest : 5|1@1+ (1,0) [0|1] "" XXX
    SG_ CF_Mdps_Flex : 8|3@1+ (1,0) [0|7] "" XXX
    SG_ CF_Mdps_FlexDisp : 11|1@1+ (1,0) [0|1] "" XXX
    SG_ CF_Mdps_CurrMode : 12|2@1+ (1,0) [0|3] "" XXX

BU_: XXX X

CM_ "AUTOGENERATED FILE, DO NOT EDIT";

CM_ "Imported file _subaru_preglobal_2015.dbc starts here";
CM_ SG_ 320 Off_Throttle_2 "Less sensitive";
CM_ SG_ 320 Throttle_Body "Throttle related";
CM_ SG_ 328 Gear "15 = P, 14 = R, 0 = N, 1-6=gear";
CM_ SG_ 328 Gear_2 "15 = P, 14 = R, 0 = N, 1-6=gear";
CM_ SG_ 353 Cruise_Button "1 = main, 2 = set shallow, 3 = set deep, 4 = resume shallow, 5 resume deep";
CM_ SG_ 354 RPM "20hz version of Transmission_Engine under Transmission";
CM_ SG_ 359 Sig1Right_Depart "right depart, hill steep and seatbelt disengage";
CM_ SG_ 359 LKAS_Inactive_2017 "1 when not steering, 0 when lkas steering";
CM_ SG_ 359 Sig1Right_Depart_Front "object in front, right depart, hill steep and seatbelt disengage alert ";
CM_ SG_ 359 Left_Depart_Front "warning after acceleration into car in front and left depart";
CM_ SG_ 359 Sig1All_Depart "Left and right depart";
CM_ SG_ 359 Sig2All_Depart "Left and right depart";
CM_ SG_ 359 All_depart_2015 "always 1 on 2017";
CM_ SG_ 604 R_APPROACHING "Faster car approaching in far right lane";
CM_ SG_ 604 L_APPROACHING "Faster car approaching in far left lane";
CM_ SG_ 604 R_RCTA "Rear cross traffic alert, only when in R gear";
CM_ SG_ 604 L_RCTA "Rear cross traffic alert, only when in R gear";
CM_ SG_ 642 COUNTER "Affected by signals";
CM_ SG_ 642 SEATBELT_FL "Driver seatbelt";
CM_ SG_ 880 Steering_Voltage_Flat "receives later than 371";
CM_ SG_ 977 UNITS "0 = Metric, 1 = Imperial";

CM_ "subaru_outback_2019.dbc starts here";

CM_ SG_ 358 Disengage_Alert "seatbelt and steep hill disengage";
CM_ SG_ 358 Cruise_Fault "No engagement until restart";
VAL_ 513 STATE 5 "FAULT_TIMEOUT" 4 "FAULT_STARTUP" 3 "FAULT_SCE" 2 "FAULT_SEND" 1 "FAULT_BAD_CHECKSUM" 0 "NO_FAULT" ;

VAL_ 780 CRUISE_SPEED 255 "no_speed" 252 "stopped";
VAL_ 780 HUD_LEAD 3 "acc_off" 2 "solid_car" 1 "dashed_car" 0 "no_car";
VAL_ 884 DASHBOARD_ALERT 0 "none" 51 "acc_problem" 55 "cmbs_problem" 75 "key_not_detected" 79 "fasten_seatbelt" 111 "lkas_problem" 131 "brake_system_problem" 132 "brake_hold_problem" 139 "tbd" 161 "door_open";
VAL_ 891 WIPERS 4 "High" 2 "Low" 0 "Off";

VAL_ 399 STEER_STATUS 6 "tmp_fault" 5 "fault_1" 4 "no_torque_alert_2" 3 "low_speed_lockout" 2 "no_torque_alert_1" 0 "normal";

VAL_ 401 GEAR_SHIFTER 32 "L" 16 "S" 8 "D" 4 "N" 2 "R" 1 "P";
VAL_ 401 GEAR 7 "L" 10 "S" 4 "D" 3 "N" 2 "R" 1 "P";
